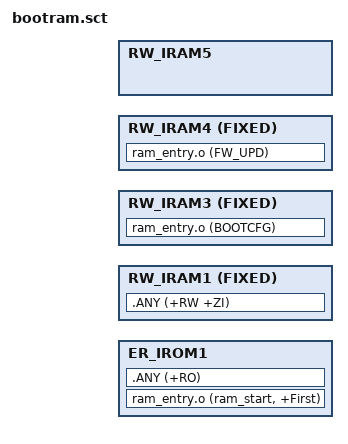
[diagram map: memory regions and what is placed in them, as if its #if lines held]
#! armcc -E

#include "..\..\..\..\inc\in_config.h"
#include "..\..\..\inc\bootram_mem.h"

#if CFG_FW_UPD_EN
#define ROM_FILL_SIZE		(FW_UPD_CODE_SIZE - ImageLength(RW_IRAM4))
#endif

; *************************************************************
; *** Scatter-Loading Description File generated by uVision ***
; *************************************************************

LR_IROM1 0x00200000 BOOTRAM_SIZE  {    ; load region size_region

	ER_IROM1 BOOTRAM_CODE_START BOOTRAM_CODE_SIZE  {  ; load address = execution address
	   ram_entry.o (ram_start, +First)
		.ANY (+RO)
	}

	RW_IRAM1 BOOTRAM_RW_START FIXED BOOTRAM_RW_SIZE {  ; RW data
		.ANY (+RW +ZI)
	}


	RW_IRAM3 BOOTRAM_BOOTCFG_START FIXED BOOTRAM_BOOTCFG_SIZE {  ; RW data
		ram_entry.o (BOOTCFG)
	}

#if CFG_FW_UPD_EN
	RW_IRAM4 FW_UPD_CODE_START FIXED FW_UPD_CODE_SIZE {  ; RW data
		ram_entry.o (FW_UPD)
	}
	RW_IRAM5 +0 FILL 0x0 ROM_FILL_SIZE {  ; RW data
	}
	
#endif	
	
}

